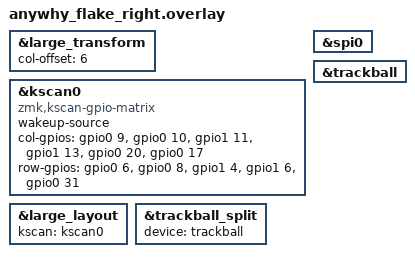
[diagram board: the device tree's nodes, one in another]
#include "anywhy_flake.dtsi"
#include "anywhy_flake_3610.dtsi"

&large_transform {
    col-offset = <6>;
};

&kscan0 {
    compatible = "zmk,kscan-gpio-matrix";
    wakeup-source;

    col-gpios
        = <&gpio0 9 GPIO_ACTIVE_HIGH>
        , <&gpio0 10 GPIO_ACTIVE_HIGH>
        , <&gpio1 11 GPIO_ACTIVE_HIGH>
        , <&gpio1 13 GPIO_ACTIVE_HIGH>
        , <&gpio0 20 GPIO_ACTIVE_HIGH>
        , <&gpio0 17 GPIO_ACTIVE_HIGH>
        ;

    row-gpios
        = <&gpio0 6 (GPIO_ACTIVE_HIGH | GPIO_PULL_DOWN)>
        , <&gpio0 8 (GPIO_ACTIVE_HIGH | GPIO_PULL_DOWN)>
        , <&gpio1 4  (GPIO_ACTIVE_HIGH | GPIO_PULL_DOWN)>
        , <&gpio1 6  (GPIO_ACTIVE_HIGH | GPIO_PULL_DOWN)>
        , <&gpio0 31  (GPIO_ACTIVE_HIGH | GPIO_PULL_DOWN)>
        ;
};

&large_layout {
    kscan = <&kscan0>;
};

&spi0 {
    status = "okay";
};

&trackball {
    status = "okay";
};

/* Enable the trackball listener on the peripheral with the sensor */
&trackball_split {
  device = <&trackball>;
  status = "okay";
};
